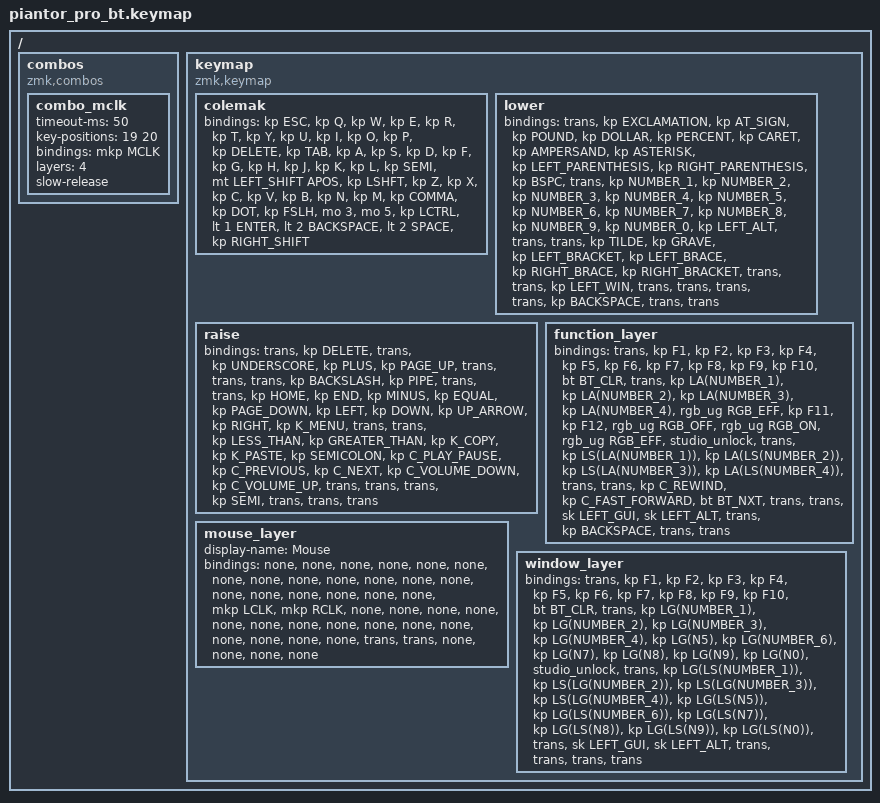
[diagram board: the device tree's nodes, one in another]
/*
 * Copyright 2024 Michał Minarowski (@n3oney)
 * 
 * Originally created for QMK by Mark Stosberg (@markstos)
 * 
 * SPDX-License-Identifier: GPL-2.0-or-later
 */

#include <dt-bindings/zmk/mouse.h>
#include <behaviors.dtsi>
#include <dt-bindings/zmk/bt.h>
#include <dt-bindings/zmk/keys.h>
#include <dt-bindings/zmk/pointing.h>
#include <dt-bindings/zmk/rgb.h>

/ {
    combos {
        compatible = "zmk,combos";

        combo_mclk {
            timeout-ms = <50>;
            key-positions = <19 20>;
            bindings = <&mkp MCLK>;
            layers = <4>;
            slow-release;
        };
    };

    keymap {
        compatible = "zmk,keymap";

        colemak {
            bindings = <
&kp ESC  &kp Q  &kp W  &kp E  &kp R  &kp T  &kp Y  &kp U  &kp I  &kp O  &kp P  &kp DELETE  &kp TAB  &kp A  &kp S  &kp D  &kp F  &kp G  &kp H  &kp J  &kp K  &kp L  &kp SEMI  &mt LEFT_SHIFT APOS  &kp LSHFT  &kp Z  &kp X  &kp C  &kp V  &kp B  &kp N  &kp M  &kp COMMA  &kp DOT  &kp FSLH  &mo 3  &mo 5  &kp LCTRL  &lt 1 ENTER  &lt 2 BACKSPACE  &lt 2 SPACE  &kp RIGHT_SHIFT
            >;
        };

        lower {
            bindings = <
&trans  &kp EXCLAMATION  &kp AT_SIGN  &kp POUND  &kp DOLLAR  &kp PERCENT  &kp CARET  &kp AMPERSAND  &kp ASTERISK  &kp LEFT_PARENTHESIS  &kp RIGHT_PARENTHESIS  &kp BSPC  &trans  &kp NUMBER_1  &kp NUMBER_2  &kp NUMBER_3  &kp NUMBER_4  &kp NUMBER_5  &kp NUMBER_6  &kp NUMBER_7  &kp NUMBER_8  &kp NUMBER_9  &kp NUMBER_0  &kp LEFT_ALT  &trans  &trans  &kp TILDE  &kp GRAVE  &kp LEFT_BRACKET  &kp LEFT_BRACE  &kp RIGHT_BRACE  &kp RIGHT_BRACKET  &trans  &trans  &kp LEFT_WIN  &trans  &trans  &trans  &trans  &kp BACKSPACE  &trans  &trans
            >;
        };

        raise {
            bindings = <
&trans  &kp DELETE  &trans  &kp UNDERSCORE  &kp PLUS  &kp PAGE_UP  &trans  &trans  &trans  &kp BACKSLASH  &kp PIPE  &trans  &trans  &kp HOME  &kp END  &kp MINUS  &kp EQUAL  &kp PAGE_DOWN  &kp LEFT  &kp DOWN  &kp UP_ARROW  &kp RIGHT  &kp K_MENU  &trans  &trans  &kp LESS_THAN  &kp GREATER_THAN  &kp K_COPY  &kp K_PASTE  &kp SEMICOLON  &kp C_PLAY_PAUSE  &kp C_PREVIOUS  &kp C_NEXT  &kp C_VOLUME_DOWN  &kp C_VOLUME_UP  &trans  &trans  &trans  &kp SEMI  &trans  &trans  &trans
            >;
        };

        function_layer {
            bindings = <
&trans  &kp F1  &kp F2  &kp F3  &kp F4  &kp F5  &kp F6  &kp F7  &kp F8  &kp F9  &kp F10  &bt BT_CLR  &trans  &kp LA(NUMBER_1)  &kp LA(NUMBER_2)  &kp LA(NUMBER_3)  &kp LA(NUMBER_4)  &rgb_ug RGB_EFF  &kp F11  &kp F12  &rgb_ug RGB_OFF  &rgb_ug RGB_ON  &rgb_ug RGB_EFF  &studio_unlock  &trans  &kp LS(LA(NUMBER_1))  &kp LA(LS(NUMBER_2))  &kp LS(LA(NUMBER_3))  &kp LA(LS(NUMBER_4))  &trans  &trans  &kp C_REWIND  &kp C_FAST_FORWARD  &bt BT_NXT  &trans  &trans  &sk LEFT_GUI  &sk LEFT_ALT  &trans  &kp BACKSPACE  &trans  &trans
            >;
        };

        mouse_layer {
            display-name = "Mouse";
            bindings = <
&none  &none  &none  &none  &none  &none  &none  &none  &none  &none  &none  &none  &none  &none  &none  &none  &none  &none  &none  &mkp LCLK  &mkp RCLK  &none  &none  &none  &none  &none  &none  &none  &none  &none  &none  &none  &none  &none  &none  &none  &trans  &trans  &none  &none  &none  &none
            >;
        };

        window_layer {
            bindings = <
&trans  &kp F1  &kp F2  &kp F3  &kp F4  &kp F5  &kp F6  &kp F7  &kp F8  &kp F9  &kp F10  &bt BT_CLR  &trans  &kp LG(NUMBER_1)  &kp LG(NUMBER_2)  &kp LG(NUMBER_3)  &kp LG(NUMBER_4)  &kp LG(N5)  &kp LG(NUMBER_6)  &kp LG(N7)  &kp LG(N8)  &kp LG(N9)  &kp LG(N0)  &studio_unlock  &trans  &kp LG(LS(NUMBER_1))  &kp LS(LG(NUMBER_2))  &kp LS(LG(NUMBER_3))  &kp LS(LG(NUMBER_4))  &kp LG(LS(N5))  &kp LG(LS(NUMBER_6))  &kp LG(LS(N7))  &kp LG(LS(N8))  &kp LG(LS(N9))  &kp LG(LS(N0))  &trans  &sk LEFT_GUI  &sk LEFT_ALT  &trans  &trans  &trans  &trans
            >;
        };
    };
};
